# PY32F0xx_DFP register map
Vendor: Puya; Series: PY32F0; File version: 1.0.0
CPU: CM0+ r0p1, little endian, no MPU, no FPU, 4 interrupt priority bits
Registers are 32-bit, read-write, reset 0x0 unless marked. A register's access mark holds for its fields unless they carry their own. Offsets are from the block's base; [hi:lo] are bit positions.

## RCC — Reset and clock control
Base 0x40021000
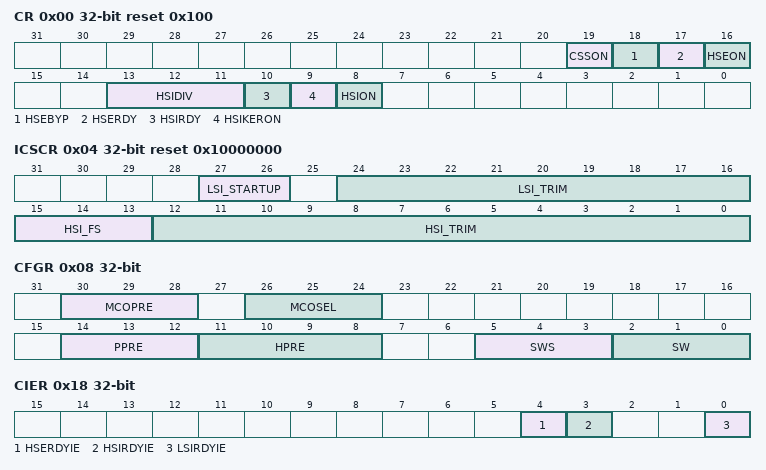
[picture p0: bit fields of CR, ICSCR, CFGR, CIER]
0x00 CR reset 0x100 — Clock control register
  [19] CSSON — Clock security system enable
  [18] HSEBYP — HSE crystal oscillator bypass
  [17] HSERDY — HSE clock ready flag
  [16] HSEON — HSE clock enable
  [13:11] HSIDIV — HSI16 clock division factor
  [10] HSIRDY — HSI16 clock ready flag
  [9] HSIKERON — HSI16 always enable for peripheral kernels
  [8] HSION — HSI16 clock enable
0x04 ICSCR reset 0x10000000 — Internal clock sources calibration register
  [27:26] LSI_STARTUP — LSI startup time
  [24:16] LSI_TRIM — LSI clock trimming
  [15:13] HSI_FS — HSI frequency selection
  [12:0] HSI_TRIM — HSI clock trimming
0x08 CFGR — Clock configuration register
  [30:28] MCOPRE — Microcontroller clock output prescaler
  [26:24] MCOSEL — Microcontroller clock output
  [14:12] PPRE — APB prescaler
  [11:8] HPRE — AHB prescaler
  [5:3] SWS ro — System clock switch status
  [2:0] SW — System clock switch
0x10 ECSCR — External clock source control register
  [3:2] HSE_FREQ — HSE clock freqency selection
0x18 CIER — Clock interrupt enable register
  [4] HSERDYIE — HSE ready interrupt enable
  [3] HSIRDYIE — HSI ready interrupt enable
  [0] LSIRDYIE — LSI ready interrupt enable
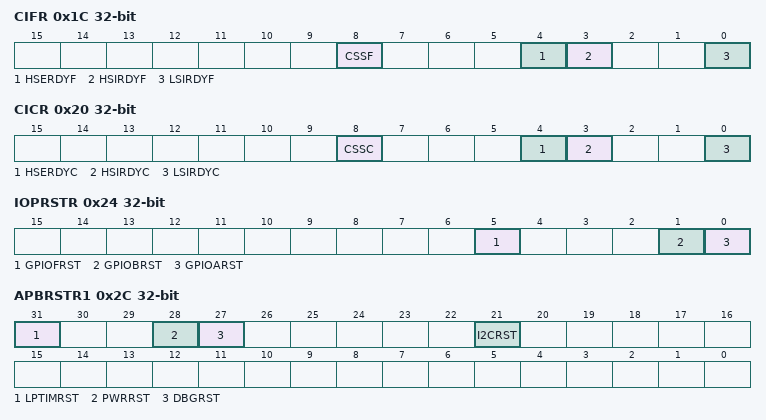
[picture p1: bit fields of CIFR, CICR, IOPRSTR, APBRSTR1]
0x1C CIFR ro — Clock interrupt flag register
  [8] CSSF — HSE clock secure system interrupt flag
  [4] HSERDYF — HSE ready interrupt flag
  [3] HSIRDYF — HSI ready interrupt flag
  [0] LSIRDYF — LSI ready interrupt flag
0x20 CICR wo — Clock interrupt clear register
  [8] CSSC — clock secure system interrupt flag clear
  [4] HSERDYC — HSE ready interrupt clear
  [3] HSIRDYC — HSI ready interrupt clear
  [0] LSIRDYC — LSI ready interrupt clear
0x24 IOPRSTR — GPIO reset register
  [5] GPIOFRST — I/O port F reset
  [1] GPIOBRST — I/O port B reset
  [0] GPIOARST — I/O port A reset
0x28 AHBRSTR — AHB peripheral reset register
  [12] CRCRST — CRC reset
0x2C APBRSTR1 — APB peripheral reset register 1
  [31] LPTIMRST — Low Power Timer reset
  [28] PWRRST — Power interface reset
  [27] DBGRST — Debug support reset
  [21] I2CRST — I2C reset
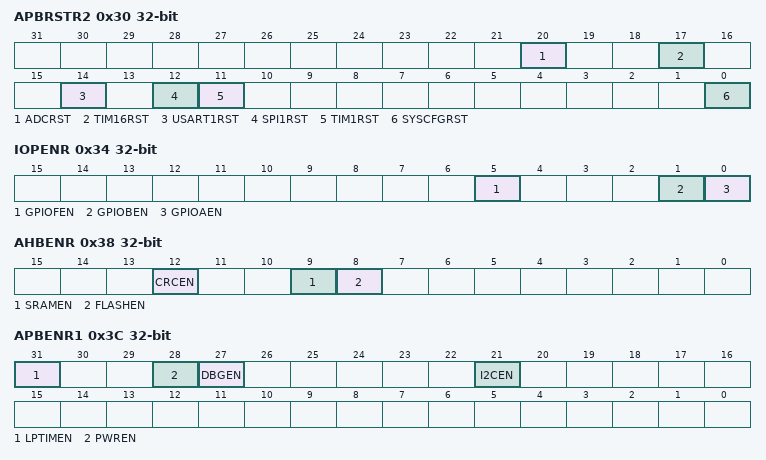
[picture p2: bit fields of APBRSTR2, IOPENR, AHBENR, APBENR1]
0x30 APBRSTR2 — APB peripheral reset register 2
  [20] ADCRST — ADC reset
  [17] TIM16RST — TIM16 timer reset
  [14] USART1RST — USART1 reset
  [12] SPI1RST — SPI1 reset
  [11] TIM1RST — TIM1 timer reset
  [0] SYSCFGRST — SYSCFG and COMP reset
0x34 IOPENR — GPIO clock enable register
  [5] GPIOFEN — I/O port F clock enable
  [1] GPIOBEN — I/O port B clock enable
  [0] GPIOAEN — I/O port A clock enable
0x38 AHBENR — AHB peripheral clock enable register
  [12] CRCEN — CRC clock enable
  [9] SRAMEN — SRAM memory interface clock enable
  [8] FLASHEN — Flash memory interface clock enable
0x3C APBENR1 — APB peripheral clock enable register 1
  [31] LPTIMEN — LPTIM clock enable
  [28] PWREN — Power interface clock enable
  [27] DBGEN — Debug support clock enable
  [21] I2CEN — I2C clock enable
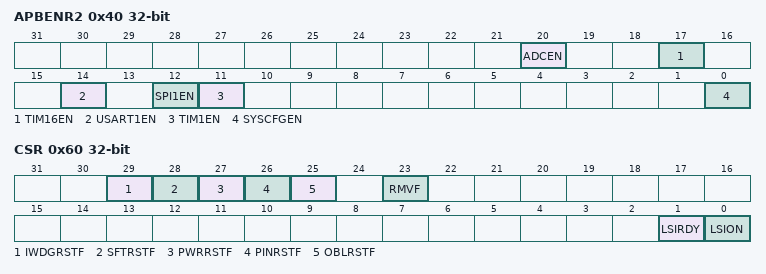
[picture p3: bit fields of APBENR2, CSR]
0x40 APBENR2 — APB peripheral clock enable register 2
  [20] ADCEN — ADC clock enable
  [17] TIM16EN — TIM16 timer clock enable
  [14] USART1EN — USART1 clock enable
  [12] SPI1EN — SPI1 clock enable
  [11] TIM1EN — TIM1 timer clock enable
  [0] SYSCFGEN — SYSCFG, COMP and VREFBUF clock enable
0x54 CCIPR — Peripherals independent clock configuration register
  [19:18] LPTIM1SEL — LPTIM1 clock source selection
0x60 CSR — Control/status register
  [29] IWDGRSTF — Independent window watchdog reset flag
  [28] SFTRSTF — Software reset flag
  [27] PWRRSTF — BOR or POR/PDR flag
  [26] PINRSTF — Pin reset flag
  [25] OBLRSTF — Option byte loader reset flag
  [23] RMVF — Remove reset flags
  [1] LSIRDY — LSI oscillator ready
  [0] LSION — LSI oscillator enable
